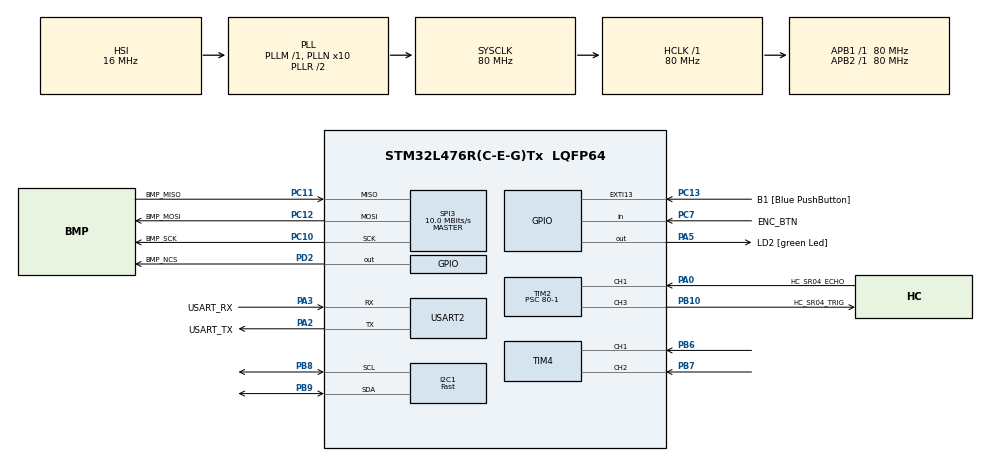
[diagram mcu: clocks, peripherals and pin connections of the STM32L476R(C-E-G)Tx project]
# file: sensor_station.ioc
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Dma.Request0=USART2_TX
Dma.USART2_TX.0.Direction=DMA_MEMORY_TO_PERIPH
Dma.USART2_TX.0.Instance=DMA1_Channel7
Dma.USART2_TX.0.MemDataAlignment=DMA_MDATAALIGN_BYTE
Dma.USART2_TX.0.MemInc=DMA_MINC_ENABLE
Dma.USART2_TX.0.Mode=DMA_NORMAL
Dma.USART2_TX.0.PeriphDataAlignment=DMA_PDATAALIGN_BYTE
Dma.USART2_TX.0.PeriphInc=DMA_PINC_DISABLE
Dma.USART2_TX.0.Priority=DMA_PRIORITY_LOW
I2C1.I2C_Speed_Mode=I2C_Fast
I2C1.Timing=0x00F12981
Mcu.Family=STM32L4
Mcu.Name=STM32L476R(C-E-G)Tx
Mcu.Package=LQFP64
NVIC.DMA1_Channel7_IRQn=true\:0\:0\:false\:false\:true\:false\:true\:true
NVIC.PriorityGroup=NVIC_PRIORITYGROUP_4
NVIC.SPI3_IRQn=true\:0\:0\:false\:false\:true\:true\:true\:true
NVIC.TIM2_IRQn=true\:0\:0\:false\:false\:true\:true\:true\:true
NVIC.TIM6_DAC_IRQn=true\:0\:0\:false\:false\:true\:true\:true\:true
NVIC.USART2_IRQn=true\:0\:0\:false\:false\:true\:true\:true\:true
PA0.GPIO_Label=HC_SR04_ECHO
PA0.Signal=S_TIM2_CH1
PA13\ (JTMS-SWDIO).GPIO_Label=TMS
PA13\ (JTMS-SWDIO).Mode=Serial_Wire
PA13\ (JTMS-SWDIO).Signal=SYS_JTMS-SWDIO
PA14\ (JTCK-SWCLK).GPIO_Label=TCK
PA14\ (JTCK-SWCLK).Mode=Serial_Wire
PA14\ (JTCK-SWCLK).Signal=SYS_JTCK-SWCLK
PA2.GPIO_Label=USART_TX
PA2.GPIO_Mode=GPIO_MODE_AF_PP
PA2.GPIO_PuPd=GPIO_NOPULL
PA2.GPIO_Speed=GPIO_SPEED_FREQ_VERY_HIGH
PA2.Mode=Asynchronous
PA2.Signal=USART2_TX
PA3.GPIO_Label=USART_RX
PA3.GPIO_Mode=GPIO_MODE_AF_PP
PA3.GPIO_PuPd=GPIO_NOPULL
PA3.GPIO_Speed=GPIO_SPEED_FREQ_VERY_HIGH
PA3.Mode=Asynchronous
PA3.Signal=USART2_RX
PA5.GPIO_Label=LD2 [green Led]
PA5.GPIO_ModeDefaultOutputPP=GPIO_MODE_OUTPUT_PP
PA5.GPIO_PuPd=GPIO_NOPULL
PA5.GPIO_Speed=GPIO_SPEED_FREQ_LOW
PA5.Signal=GPIO_Output
PB10.GPIO_Label=HC_SR04_TRIG
PB10.Signal=S_TIM2_CH3
PB3\ (JTDO-TRACESWO).GPIO_Label=SWO
PB3\ (JTDO-TRACESWO).Signal=SYS_JTDO-SWO
PB6.Signal=S_TIM4_CH1
PB7.Signal=S_TIM4_CH2
PB8.Mode=I2C
PB8.Signal=I2C1_SCL
PB9.Mode=I2C
PB9.Signal=I2C1_SDA
PC10.GPIO_Label=BMP_SCK
PC10.Mode=Full_Duplex_Master
PC10.Signal=SPI3_SCK
PC11.GPIO_Label=BMP_MISO
PC11.Mode=Full_Duplex_Master
PC11.Signal=SPI3_MISO
PC12.GPIO_Label=BMP_MOSI
PC12.Mode=Full_Duplex_Master
PC12.Signal=SPI3_MOSI
PC13.GPIO_Label=B1 [Blue PushButton]
PC13.GPIO_ModeDefaultEXTI=GPIO_MODE_IT_FALLING
PC13.GPIO_PuPd=GPIO_NOPULL
PC13.Signal=GPXTI13
PC14-OSC32_IN\ (PC14).Mode=LSE-External-Oscillator
PC14-OSC32_IN\ (PC14).Signal=RCC_OSC32_IN
PC15-OSC32_OUT\ (PC15).Mode=LSE-External-Oscillator
PC15-OSC32_OUT\ (PC15).Signal=RCC_OSC32_OUT
PC7.GPIO_Label=ENC_BTN
PC7.GPIO_PuPd=GPIO_PULLUP
PC7.Signal=GPIO_Input
PD2.GPIO_Label=BMP_NCS
PD2.PinState=GPIO_PIN_SET
PD2.Signal=GPIO_Output
PH0-OSC_IN\ (PH0).Signal=RCC_OSC_IN
PH1-OSC_OUT\ (PH1).Signal=RCC_OSC_OUT
ProjectManager.HeapSize=0x200
ProjectManager.StackSize=0x400
ProjectManager.TargetToolchain=CMake
RCC.ADCFreq_Value=64000000
RCC.AHBFreq_Value=80000000
RCC.APB1Freq_Value=80000000
RCC.APB1TimFreq_Value=80000000
RCC.APB2Freq_Value=80000000
RCC.APB2TimFreq_Value=80000000
RCC.CortexFreq_Value=80000000
RCC.HCLKFreq_Value=80000000
RCC.HSE_VALUE=8000000
RCC.HSI_VALUE=16000000
RCC.MSI_VALUE=4000000
RCC.PLLN=10
RCC.PLLSourceVirtual=RCC_PLLSOURCE_HSI
RCC.PREFETCH_ENABLE=1
RCC.SYSCLKFreq_VALUE=80000000
RCC.SYSCLKSource=RCC_SYSCLKSOURCE_PLLCLK
RCC.USBFreq_Value=64000000
RCC.VCOOutputFreq_Value=160000000
SH.S_TIM2_CH1.0=TIM2_CH1,Input_Capture1_from_TI1
SH.S_TIM2_CH3.0=TIM2_CH3,PWM Generation3 CH3
SH.S_TIM4_CH1.0=TIM4_CH1,Encoder_Interface
SH.S_TIM4_CH2.0=TIM4_CH2,Encoder_Interface
SPI3.BaudRatePrescaler=SPI_BAUDRATEPRESCALER_8
SPI3.CalculateBaudRate=10.0 MBits/s
SPI3.DataSize=SPI_DATASIZE_8BIT
SPI3.Direction=SPI_DIRECTION_2LINES
SPI3.Mode=SPI_MODE_MASTER
SPI3.VirtualType=VM_MASTER
TIM2.Channel-Input_Capture1_from_TI1=TIM_CHANNEL_1
TIM2.Channel-Input_Capture2_from_TI1_63=TIM_CHANNEL_2
TIM2.Channel-PWM\ Generation3\ CH3=TIM_CHANNEL_3
TIM2.ICPolarity_CH2=TIM_INPUTCHANNELPOLARITY_FALLING
TIM2.Period=1000000-1
TIM2.Prescaler=80-1
TIM2.Pulse-PWM\ Generation3\ CH3=10
TIM4.EncoderMode=TIM_ENCODERMODE_TI12
TIM4.IC1Filter=10
TIM6.Period=10000-1
TIM6.Prescaler=80-1
USART2.VirtualMode-Asynchronous=VM_ASYNC
VP_TIM2_VS_indirect_ch1.Mode=Input_Capture2_from_TI1_63
VP_TIM6_VS_ClockSourceINT.Mode=Enable_Timer
board=NUCLEO-L476RG

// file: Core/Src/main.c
/* USER CODE BEGIN Header */
/**
  ******************************************************************************
  * @file           : main.c
  * @brief          : Main program body
  ******************************************************************************
  * @attention
  *
  * Copyright (c) 2026 STMicroelectronics.
  * All rights reserved.
  *
  * This software is licensed under terms that can be found in the LICENSE file
  * in the root directory of this software component.
  * If no LICENSE file comes with this software, it is provided AS-IS.
  *
  ******************************************************************************
  */
/* USER CODE END Header */
#include "main.h"
#include "dma.h"
#include "i2c.h"
#include "spi.h"
#include "tim.h"
#include "usart.h"
#include "gpio.h"

/* USER CODE BEGIN Includes */
#include "app.h"
/* USER CODE END Includes */

void SystemClock_Config(void);

int main(void)
{

  /* MCU Configuration--------------------------------------------------------*/

  /* Reset of all peripherals, Initializes the Flash interface and the Systick. */
  HAL_Init();

  /* Configure the system clock */
  SystemClock_Config();

  /* Initialize all configured peripherals */
  MX_GPIO_Init();
  MX_DMA_Init();
  MX_TIM4_Init();
  MX_TIM6_Init();
  MX_USART2_UART_Init();
  MX_I2C1_Init();
  MX_SPI3_Init();
  MX_TIM2_Init();
  /* USER CODE BEGIN 2 */
  app_init();
  /* USER CODE END 2 */

  /* Infinite loop */
  /* USER CODE BEGIN WHILE */
  while (1)
  {
    app_step();
    /* USER CODE END WHILE */

  }
}

void SystemClock_Config(void)
{
  RCC_OscInitTypeDef RCC_OscInitStruct = {0};
  RCC_ClkInitTypeDef RCC_ClkInitStruct = {0};

  /** Configure the main internal regulator output voltage
  */
  if (HAL_PWREx_ControlVoltageScaling(PWR_REGULATOR_VOLTAGE_SCALE1) != HAL_OK)
  {
    Error_Handler();
  }

  /** Initializes the RCC Oscillators according to the specified parameters
  * in the RCC_OscInitTypeDef structure.
  */
  RCC_OscInitStruct.OscillatorType = RCC_OSCILLATORTYPE_HSI;
  RCC_OscInitStruct.HSIState = RCC_HSI_ON;
  RCC_OscInitStruct.HSICalibrationValue = RCC_HSICALIBRATION_DEFAULT;
  RCC_OscInitStruct.PLL.PLLState = RCC_PLL_ON;
  RCC_OscInitStruct.PLL.PLLSource = RCC_PLLSOURCE_HSI;
  RCC_OscInitStruct.PLL.PLLM = 1;
  RCC_OscInitStruct.PLL.PLLN = 10;
  RCC_OscInitStruct.PLL.PLLP = RCC_PLLP_DIV7;
  RCC_OscInitStruct.PLL.PLLQ = RCC_PLLQ_DIV2;
  RCC_OscInitStruct.PLL.PLLR = RCC_PLLR_DIV2;
  if (HAL_RCC_OscConfig(&RCC_OscInitStruct) != HAL_OK)
  {
    Error_Handler();
  }

  /** Initializes the CPU, AHB and APB buses clocks
  */
  RCC_ClkInitStruct.ClockType = RCC_CLOCKTYPE_HCLK|RCC_CLOCKTYPE_SYSCLK
                              |RCC_CLOCKTYPE_PCLK1|RCC_CLOCKTYPE_PCLK2;
  RCC_ClkInitStruct.SYSCLKSource = RCC_SYSCLKSOURCE_PLLCLK;
  RCC_ClkInitStruct.AHBCLKDivider = RCC_SYSCLK_DIV1;
  RCC_ClkInitStruct.APB1CLKDivider = RCC_HCLK_DIV1;
  RCC_ClkInitStruct.APB2CLKDivider = RCC_HCLK_DIV1;

  if (HAL_RCC_ClockConfig(&RCC_ClkInitStruct, FLASH_LATENCY_4) != HAL_OK)
  {
    Error_Handler();
  }
}

void Error_Handler(void)
{
  __disable_irq();
  while (1)
  {
  }
}
